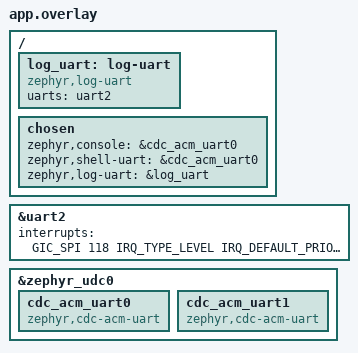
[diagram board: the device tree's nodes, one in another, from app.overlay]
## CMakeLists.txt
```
# SPDX-License-Identifier: Apache-2.0
cmake_minimum_required(VERSION 3.20.0)
find_package(Zephyr REQUIRED HINTS $ENV{ZEPHYR_BASE})
project(moru)

# 빌드 시각. configure 시점에 정해진다 — build.sh 가 -p always 라 매번 갱신되지만,
# ninja 만 직접 돌리면 옛 시각이 남는다.
# __DATE__/__TIME__ 대신 CMake 를 쓰는 이유는 재현 빌드다. ccache 영향은
# 어느 쪽이든 이 두 파일 재컴파일로 같다.
string(TIMESTAMP MORU_BUILD_TIME "%Y-%m-%d %H:%M:%S" UTC)
target_compile_definitions(app PRIVATE MORU_BUILD_TIME="${MORU_BUILD_TIME} UTC")

#
# ⚠ 작업 트리가 더러운지(커밋 전 변경이 있는지) 박는다.
#
# 왜 필요한가: APP_BUILD_VERSION 은 `git describe` 에 **--dirty 가 없다.**
# 그래서 **커밋 전 트리로 빌드한 이미지가 HEAD 해시로 찍힌다.** 2026-11-07 에
# 실기에서 "8 MiB 상한이 없는 커밋(54da428)" 으로 보이는 이미지가 실제로는
# 상한을 갖고 있어 한참 혼동했다.
#
# 왜 여기서 하는가: Zephyr 의 app_version.h 는 **별도 cmake 스크립트 호출**로
# 생성되고 최상위 -DAPP_BUILD_VERSION 이 그 호출에 전달되지 않는다
# (cmake/gen_version_h.cmake 는 자기 인자만 본다). 게다가 그 매크로는
# **따옴표 없는 토큰**이라 `-dirty` 같은 하이픈을 담기에도 부적합하다.
# 그래서 문자열로 직접 주입한다.
execute_process(COMMAND git -C ${CMAKE_CURRENT_SOURCE_DIR} status --porcelain
                OUTPUT_VARIABLE MORU_GIT_STATUS
                OUTPUT_STRIP_TRAILING_WHITESPACE ERROR_QUIET)
if(MORU_GIT_STATUS STREQUAL "")
  set(MORU_GIT_DIRTY "")
else()
  set(MORU_GIT_DIRTY "-dirty")
endif()
target_compile_definitions(app PRIVATE MORU_GIT_DIRTY="${MORU_GIT_DIRTY}")

# 보드 모델은 moru_boot.c 의 고정 문자열이다.
# DT 루트의 model 속성은 바인딩에 없어 매크로가 생성되지 않고(DT_PROP 불가)
# dt_prop() 도 비어 돌아온다. zephyr.dts 를 정규식으로 긁는 방법은 되지만,
# 이 앱은 이미 보드 전용이고(GPIO0 주소·SoC 문구가 하드코딩) 이 값은 배너
# 장식 한 줄이라 그 취약함을 안고 갈 값이 아니다.
# → 그래서 src/moru.h 의 MORU_MODEL 고정 문자열로 둔다.

# 소스 네 개를 모두 빌드한다 (2026-11-06, B1·B2 완료 상태).
#   main.c       LED 하트비트 + main
#   moru_mark.c  초기 부팅 동기 마커 — uart2 에 직접 (USB 가 무음일 때의 눈)
#   moru_boot.c  Linux dmesg 형식 부팅 메시지 + 로그 타임스탬프 기준점
#   moru_shell.c `moru` 명령 (info · reboot)
#
# ⚠ 과거에 moru_stage.c 가 있었고 2026-11-06 에 삭제했다 — PRE_KERNEL_1 에서
#   device_map() 을 불러 보드를 죽이는 파일이었다. kernel/init.c 의
#   z_mem_manage_init()(:293)이 PRE_KERNEL_1(:560)·PRE_KERNEL_2(:564) 보다
#   뒤, POST_KERNEL(:300) 바로 앞에서 돈다. 진단 장치가 피검체를 죽인
#   사례이고 (docs/bringup-rules.md 규칙 5), 남겨 두면 다음 사람이 빌드에
#   넣고 같은 함정을 밟으므로 지웠다.
# drivers/hwinfo/hwinfo_rk3566.h 를 "hwinfo_rk3566.h" 로 쓸 수 있게 한다.
# (저장소 루트는 CMakeLists.txt 의 두 단계 위)
target_include_directories(app PRIVATE
  ${CMAKE_CURRENT_SOURCE_DIR}/../../drivers/hwinfo
  # udc_dwc3_regs.h — moru usb 가 dwc3 레지스터를 직접 읽는다. 드라이버
  # 소스는 건드리지 않고 레지스터 정의만 재사용하므로 중복 정의가 없다.
  ${CMAKE_CURRENT_SOURCE_DIR}/../../drivers/usb/udc)

target_sources(app PRIVATE src/main.c src/moru_mark.c src/moru_boot.c
                           src/moru_shell.c src/moru_usbd.c
                           src/moru_htop.c src/moru_fatal.c)
```

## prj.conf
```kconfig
# USB 디바이스 스택은 켜되, 콘솔은 UART2 로 둔다.
#
# 스택이 켜져야 usbd 가 udc_init()/udc_enable() 을 부르고 그래야 dwc3
# 드라이버가 실제로 돈다. 콘솔을 CDC-ACM 으로 보내면 드라이버가 실패할 때
# 실패 원인을 알려 줄 로그 자체가 사라지므로, 콘솔은 UART2 에 남긴다.
CONFIG_SERIAL=y
CONFIG_CONSOLE=y
CONFIG_UART_CONSOLE=y
CONFIG_STDOUT_CONSOLE=y
CONFIG_UART_LINE_CTRL=y

CONFIG_USB_DEVICE_STACK_NEXT=y
CONFIG_USBD_CDC_ACM_CLASS=y
# 부팅 때 스택을 자동으로 올린다 — 앱 코드 없이 udc_init/udc_enable 이 불린다
# ⚠ 끈다 — 이 자동 경로는 CDC-ACM 인스턴스를 **하나만** 등록한다.
#   subsys/usb/device_next/app/cdc_acm_serial.c:65 가
#   usbd_register_class(..., "cdc_acm_0", ...) 를 부르고 함수 이름도
#   register_cdc_acm_0 다. 그 Kconfig help 도 "다른 USB 기능이 필요 없는
#   앱의 기본 시리얼 백엔드 전용" 이라고 적고 있다.
#
#   실기 증상(2026-11-06): cdc_acm_uart1 노드를 추가해도 호스트에 포트가
#   하나만 보였다. 드라이버 인스턴스는 생겨 device_is_ready() 가 true 인데
#   USB 디스크립터에는 인터페이스가 2개(CDC 하나)뿐이었다.
#
#   → src/moru_usbd.c 가 대신 구성한다. usbd_register_all_classes() 로
#     사용 가능한 인스턴스를 전부 등록하므로 CDC 를 더 늘려도 코드를
#     고치지 않는다.
CONFIG_CDC_ACM_SERIAL_INITIALIZE_AT_BOOT=n
# ⚠ CDC_ACM_SERIAL_PID·PRODUCT_STRING 은 INITIALIZE_AT_BOOT 하위 심볼이라
#   그것을 끈 지금은 존재하지 않는다. VID·PID·문자열은 src/moru_usbd.c 가
#   정한다 (MORU_USB_VID 0x2fe3 · MORU_USB_PID 0x0005 ·
#   "MoruLab" / "MoruLab Zephyr RTOS"). 호스트에 보이는 이름이므로 그쪽을
#   고친다.

# 진단이 목적이므로 USB 쪽 로그를 모두 켠다
CONFIG_LOG=y
# DBG 는 줄 수가 너무 많다 — 타이밍에 영향을 준다. 판정에 필요한 INF 만.
CONFIG_UDC_DRIVER_LOG_LEVEL_INF=y
CONFIG_USBD_LOG_LEVEL_INF=y
# ⚠ INF 로 두면 **수신한 모든 바이트가 hexdump 된다** —
#   usbd_cdc_acm.c:315 의 LOG_HEXDUMP_INF(buf->data, buf->len, "").
#   OTA 로 171 KB 를 받으면 로그가 폭발하고, 그것을 다시 CDC 로 내보내려
#   하면서 전송이 사실상 멈춘다(실기에서 120초를 넘겼다). cdc_acm_fifo_read
#   안의 LOG_INF 도 같다. Zephyr 공식 overlay-usb.conf 가
#   USBD_CDC_ACM_LOG_LEVEL_OFF=y 를 쓰는 이유가 이것이다.
#
#   WRN 으로 둔다 — OFF 가 아니라 WRN 인 이유는 "Invoked by inappropriate
#   context" 같은 실제 경고는 봐야 하기 때문이다.
# ⚠ WRN 이어야 한다 — INF 면 usbd_cdc_acm.c:315 의 LOG_HEXDUMP_INF 가
#   수신 바이트를 전부 찍어 대량 전송을 따라가지 못한다. 진단 때 INF 로
#   켜서 수신 경로가 정상임을 확인했고(64바이트 완전 수신, 4096 에서
#   96 %), 그 2 % 부족도 hexdump 지연 때문이었다.
#   "Invoked by inappropriate context" 같은 실제 경고는 WRN 에서 보인다.
CONFIG_USBD_CDC_ACM_LOG_LEVEL_WRN=y

# ⚠ 즉시 출력 모드. 어딘가에서 멈추면 버퍼에 남은 로그가 날아가므로,
#   한 줄씩 바로 내보내 '어디까지 갔는지' 를 알 수 있게 한다.
# ⚠ 즉시 모드를 쓰지 않는다 — 이것이 열거 실패의 원인이었다.
#
#   즉시 모드는 로그 한 줄을 그 자리에서 UART 로 밀어내며 스레드를 멈춘다.
#   115200 에서 100자는 약 9 ms 이고, 리셋 처리 하나가 12줄 이상을 찍으니
#   100 ms 가 넘는다. USB 규격은 SET_ADDRESS 가 50 ms 안에 완료되어야
#   한다고 정하므로, 로그가 그 예산을 통째로 먹고 호스트가 타임아웃·리셋을
#   반복했다 (실기에서 26~38회).
#
#   지연 모드는 로그 스레드가 따로 내보내므로 드라이버 스레드를 막지 않는다.
CONFIG_LOG_MODE_DEFERRED=y
# main 이 USB CDC-ACM 이라 **터미널을 열 때까지 백엔드가 붙지 않는다.**
# deferred 로그는 그동안 이 버퍼에 쌓이고, 넘치면 오래된 것부터 조용히
# 버려진다 — 그러면 부팅 로그 앞부분이 사라져 "무음"처럼 보인다.
# 부팅 로그가 ~45줄이라 8192 로도 될 것 같지만 여유가 없다. 8 KiB 를 더
# 쓰는 값이 1 MiB 중에서 싸다 (교란 변수를 미리 없앤다).
CONFIG_LOG_BUFFER_SIZE=16384

# ⚠ 실기에서 "xlat tables low: 7 of 8 in use" 경고가 났다. device_map 을
#   여러 번 쓰므로(dwc3, GPIO, USB2PHY GRF) 기본값 8 로는 빠듯하다.
CONFIG_MAX_XLAT_TABLES=24

# ⚠ 실기에서 크래시했다 — ELR 과 lr 이 같은 쓰레기 주소(0xffffff80ffffffd0)
#   였다. ret 이 망가진 복귀 주소로 돌아간 것, 즉 스택 손상이다.
#
#   드라이버 스레드 기본값이 1024 바이트인데 CONFIG_LOG_MODE_IMMEDIATE 는
#   호출자 스택에서 로그를 포매팅·출력하므로 훨씬 많이 쓴다. 핸들러 하나가
#   여러 줄을 찍으면 넘친다.
CONFIG_UDC_DWC3_STACK_SIZE=4096

# 다음에 또 넘치면 '쓰레기 점프' 가 아니라 명확한 메시지로 보이게 한다.
# 스택 손상이 원인이 아니었다면 이 설정들이 그것도 알려 준다.
# CONFIG_HW_STACK_PROTECTION 은 이 arm64 타깃에서 지원되지 않는다.
# 소프트웨어 감시자(sentinel)로 대신한다 — 넘치면 명확히 알려 준다.
# 넘침을 쓰레기 점프가 아니라 명확한 메시지로 보이게 한다.
# (기동을 깨뜨린 것은 FRAME_POINTER 였고 이것은 무해했다)
CONFIG_STACK_SENTINEL=y
CONFIG_THREAD_NAME=y
CONFIG_THREAD_STACK_INFO=y
# CONFIG_STACK_USAGE=y   # 기동 실패 원인 가리기 위해 임시로 끔
# CONFIG_INIT_STACKS=y   # 기동 실패 원인 가리기 위해 임시로 끔

# CONFIG_DEBUG_THREAD_INFO=y   # 기동 실패 원인 가리기 위해 임시로 끔

# ── 실험 1 (2026-11-06): 역추적 재시험 ────────────────────────────────
#
# 과거 기록: FRAME_POINTER / EXCEPTION_STACK_TRACE 를 켜면 Zephyr 가
# 기동조차 하지 못했다 (LED 도 콘솔도 무음).
#
# ⚠ 그 증상은 INIT_STACKS 와 **똑같았고, 그쪽 원인은 EL2 데이터 캐시였다.**
#   (ARM64_DCACHE_ALL_OPS + ARM64_BOOT_DISABLE_DCACHE 로 해결, 실기 확인)
#   프레임 포인터도 스택을 더 건드리므로 같은 원인일 수 있다. 캐시 두 설정이
#   켜진 지금 구성에서 다시 시험한다.
#
# 한 줄로 체인 넷이 켜진다 — 쪼갤 수 없다:
#   ARCH_HAS_STACKWALK      default y, depends on FRAME_POINTER
#                           (arch/arm64/core/Kconfig:210, CPU_CORTEX_A 안)
#     -> ARCH_STACKWALK     default y (arch/Kconfig:489)
#       -> EXCEPTION_STACK_TRACE  default y (subsys/debug/Kconfig:317)
# 즉 FRAME_POINTER 없이는 나머지가 선택 자체가 안 된다. 과거 기록이
# "둘 다"로 적은 것은 사실상 하나였다.
#
# 전제조건은 이미 넣었다 — SHELL_STACK_SIZE=4096 (실측 71 % 근거, 아래).
# 프레임 포인터는 스택을 더 쓰므로 3072 에서 시험하면 "기동 실패"와
# "셸 스택 넘침"을 가릴 수 없다.
#
# 판정:
#   부팅 + Moru > → 역추적을 되찾았다. 남은 B1~B4 의 디버깅 비용이 내려간다
#   무음           → 캐시와 무관한 별개 원인. 이 줄을 지우고 돌아간다
#                    (동작판 사본: 스크래치패드 zephyr-usbmain-good.bin
#                     146048 B, config-usbmain-good)
#
# ✅ 안전한 검증 수단이 함께 생겼다 — CONFIG_KERNEL_THREAD_SHELL_UNWIND 가
#   자동으로 켜져 `kernel thread unwind [<id16진수>]` 명령이 붙는다
#   (subsys/shell/modules/kernel_service/thread/unwind.c:53, 인자를 빼면
#    현재 스레드). 살아 있는 스레드의 콜 스택을 찍으므로 **고장 코드를
#   넣지 않고** 역추적을 확인할 수 있다 — 일부러 깨뜨리는 것은 규칙 5 가
#   금지하는 패턴이고(moru_stage.c 가 그렇게 태어났다) 이제 필요도 없다.
#
#   주소를 함수 이름으로 바꾸려면:
#     ~/zephyr-sdk-1.0.1/gnu/aarch64-zephyr-elf/bin/aarch64-zephyr-elf-addr2line \
#       -e /tmp/claude-501/rz3e-build/zephyr/zephyr.elf -f -C <주소>
CONFIG_FRAME_POINTER=y

# ⚠ usbd 스레드 스택 — Zephyr 기본값 1024 로는 넘친다 (실기 확인:
#   "FATAL ERROR 2: Stack overflow", Current thread: usbd).
#
#   1024 는 32비트 MCU 기준 값이다. arm64 는 64비트 레지스터 31개라
#   문맥 저장만으로도 크고, CONFIG_LOG_MODE_IMMEDIATE 는 로그를 호출자
#   스택에서 포매팅한다. 이 보드의 다른 스택(main·workqueue·ISR·idle)은
#   이미 4096 인데 이것만 기본값으로 남아 있었다.
CONFIG_USBD_THREAD_STACK_SIZE=4096

# 직렬번호 문자열 디스크립터를 위해 hwinfo 를 켠다.
# 구현은 drivers/hwinfo/hwinfo_rk3566.c (자리표 — 주석 참고).
CONFIG_HWINFO=y

# ── 1단계 최소 시험: usbuart 와의 차이는 이 두 줄이 전부다 ────────────────
#
# 5줄까지 줄였는데도 무음이었다. 그 중 셋(SHELL_STACK_SIZE, DW8250,
# LOG_BACKEND_UART)은 내가 추측으로 더한 것이고 기능에 필수가 아니다.
# 기능이 요구하는 최소치만 남긴다. 이것도 무음이면 CONFIG_SHELL 자체가
# 지금 이 보드와 맞지 않는다는 뜻이고, 그건 훨씬 근본적인 발견이다.
#
# 뺀 것과 이유:
#   SHELL_STACK_SIZE=8192  → 기본값(arm64 3072)을 쓴다. 더한 근거가 추측이었다
#   UART_NS16550_DW8250_DW_APB=y → poll_out 은 LSR_THRE 를 쓰므로 콘솔과
#       무관하고(uart_ns16550.c:986), RK3566 에 USR 이 있는지 TRM 으로
#       확인하지 않았다
#   LOG_BACKEND_UART=y → 셸 백엔드와 같은 UART 에 두 번째 백엔드를 붙이는
#       것이라 그 자체가 미검증이다
CONFIG_SHELL=y
CONFIG_SHELL_PROMPT_UART="Moru > "

# ⚠ 셸 백엔드를 폴링 모드로. SHELL=y 가 이 보드에 들여오는 유일하게 새로운
#   것이 UART 인터럽트이고, 이 보드는 그 경로를 한 번도 쓴 적이 없다
#   (기존 세 앱은 전부 셸이 없다). 폴링이면 인터럽트를 아예 쓰지 않는다.
#   이것으로 부팅하면 인터럽트 경로가 범인으로 확정되고, 그래도 죽으면
#   인터럽트 가설은 완전히 폐기된다.
# ⚠ 인터럽트 구동으로 바꿨다 (2026-11-06) — 로그가 잘리는 문제 때문이다.
#
#   증상: 터미널을 열면 부팅 로그가 쏟아지다 중간에 끊긴다
#   (ep 0x81 mps=16 까지만). 그런데 shell stats show 는 Lost logs: 0 이다.
#
#   원인: cdc_acm_poll_out(usbd_cdc_acm.c:1014)이 링버퍼가 차면
#   **조용히 버린다** (flow_ctrl 이 false — DT hw-flow-control 이 없다).
#   터미널을 열기 전 로그가 그렇게 버려진다. Lost logs 는 셸 로그 백엔드의
#   큐 드롭만 세므로 이 버림은 집계되지 않는다.
#
#   해결: CONFIG_SHELL_BACKEND_SERIAL_CHECK_DTR — DTR 이 올 때까지 TX 를
#   막아 버리지 않고 기다린다. 그것이 **인터럽트 모드 전용**이다
#   (Kconfig.backends:148).
#
#   폴링을 쓴 원래 이유는 uart2 의 GIC 트리거 타입이 불확실했기
#   때문인데, **셸이 CDC 로 옮겨간 뒤 그 이유가 사라졌다** — CDC 의
#   인터럽트는 USB 컨트롤러(SPI 169, 라이브 DT 로 검증)가 낸다.
#   진단 빌드(셸이 UART2)는 diag-uart.conf 로 폴링을 되돌린다.
CONFIG_SHELL_BACKEND_SERIAL_API_INTERRUPT_DRIVEN=y
# ⚠ CHECK_DTR 을 **껐다** (2026-11-06 저녁). 같은 기전이 반대로 물었다.
#
#   증상: 터미널 앱에서 수 초마다 "Connection lost — auto-reconnecting" 이
#   반복되고 타이핑한 글자가 유실됐다 (`moru htop` 이 `mhtop` 으로 들어갔다).
#
#   가린 방법: 포트를 쥐고 **DTR 을 내리지 않는** 리더로 140초간 1초마다
#   `kernel uptime` 을 물었다 — 끊김 0, 응답 90/90, 재열거 0, 재부팅 0,
#   가동시간 단조 증가. 보드·케이블·전원은 멀쩡하다. 침묵이 아니라
#   **90회 전부 응답했다는 양성 증거**다.
#
#   원인: uart_dtr_check()(shell_uart.c:135-153)가 DTR 이 내려가 있으면
#   셸 TX 를 막는다. 앱이 DTR 을 흔들거나 tty 를 여닫으면 출력이 멈추고,
#   앱은 그 침묵을 끊김으로 보고 다시 열며, 그 창의 입력은 버려진다.
#
#   왜 이제 꺼도 되는가: 이 설정을 켠 이유(위 — 터미널을 열기 전 CDC
#   poll_out 이 로그를 조용히 버리는 것)가 **약해졌다.** app.overlay 의
#   chosen zephyr,log-uart 로 로그를 uart2 에 복제했으므로 터미널을 열기
#   전 로그도 전부 uart2 에 남는다. CDC 에서 버려지는 것이 더 이상 유일한
#   기록이 아니다.
#
#   대가: 터미널을 열기 전 CDC 출력은 버려진다(열고 엔터 한 번이면
#   프롬프트가 나온다). 이득: 터미널 앱의 DTR 동작에 의존하지 않는다.
# CONFIG_SHELL_BACKEND_SERIAL_CHECK_DTR=y

# ⚠ 셸 로그 백엔드의 큐 — CHECK_DTR 만으로는 부족했다.
#
#   CHECK_DTR 을 켜니 로그가 EP 6개까지 온전히 나왔지만
#   "--- 27 messages dropped ---" 가 남았다. CHECK_DTR 이 **버림을
#   집계되게** 만든 것이고(이전에는 CDC poll_out 이 조용히 버렸다),
#   이제 드롭되는 곳은 셸 로그 백엔드의 큐다.
#
#   기본값은 큐 512 바이트 · 타임아웃 100 ms 다. 부팅 로그가 60여 줄이고
#   터미널을 열기까지 수십 초가 걸리므로 모자란다.
#   타임아웃을 늘리면 로그를 넣는 쪽이 더 기다려 준다 — 부팅 중 몇백 ms
#   지연은 무해하고(deferred 모드라 호출자를 막지 않는다) 로그를 잃는
#   것보다 낫다.
CONFIG_SHELL_BACKEND_SERIAL_LOG_MESSAGE_QUEUE_SIZE=8192
CONFIG_SHELL_BACKEND_SERIAL_LOG_MESSAGE_QUEUE_TIMEOUT=1000

# ── KERNEL_SHELL 이 imply 로 끌고 오는 것들을 명시적으로 끈다 ────────────
#
# .config 를 usbuart 와 직접 비교해 보니 내가 쓴 2줄이 아니라 70여 개가
# 달랐다. CONFIG_SHELL=y 한 줄이 KERNEL_SHELL·DEVICE_SHELL·DEVMEM_SHELL·
# DATE_SHELL 을 기본 y 로 켜고, KERNEL_SHELL 이 다시 INIT_STACKS 와
# THREAD_MONITOR 를 imply 한다. imply 는 강제가 아니라 끌 수 있다.
#
# INIT_STACKS 가 특히 중요하다 — 동작하는 usbuart 에는 없고 실패한 모든
# 빌드에 있었다. usbuart/prj.conf:61-62 가 "기동 실패 원인 가리려고 껐다"
# 고 적어 둔 그 설정이다. arm64 리셋 경로(reset.S:204-215)에서 MMU 와
# 콘솔보다 먼저 ISR 스택을 0xAA 로 칠한다. 이 보드의 수치로는 그 루프가
# 정상 종료하는 것을 확인했지만(시작·끝 차이 0xFF8), 상관관계가 분명하니
# 변수를 줄인다.
#
# DEVMEM_SHELL 은 임의 물리 메모리 쓰기라 어차피 끄려던 것이다.
# ── A 시험: 범인 특정 ────────────────────────────────────────────────────
#
# 네 설정을 전부 끄니 부팅했다. 이제 어느 것이 범인인지 가린다.
#
# 기능을 직접 시험하는 쪽으로 설계했다. kernel thread list/stacks 는
# INIT_STACKS + THREAD_MONITOR + THREAD_STACK_INFO 셋 모두를 요구한다
# (thread/Kconfig:16-18,26-28). 그래서 그 셋을 켜고 나머지 둘은 끈다.
#   부팅하면 → 사용자가 고른 "스레드·스택" 명령을 바로 얻는다
#   실패하면 → 범인이 INIT_STACKS 또는 THREAD_MONITOR 로 좁혀진다
#              (DEVMEM/DATE 는 셸 명령만 더하므로 무죄 쪽에 가깝다)
#
# THREAD_STACK_INFO 와 THREAD_NAME 은 usbuart 설정에 이미 있다.
# A-2 시험 결과 반영:
#   넷 다 끈 판(777091b)  → 부팅 ✅ (Moru > 프롬프트·help 동작)
#   INIT_STACKS+THREAD_MONITOR 켠 판(464a4ce) → 무음 ❌
#   → DEVMEM_SHELL·DATE_SHELL 은 무죄 (두 판 모두 꺼져 있었다)
#   → 범인은 INIT_STACKS 또는 THREAD_MONITOR
#
# 이제 둘을 가른다. INIT_STACKS 는 arm64 리셋 경로(reset.S:204-215)에서
# MMU·콘솔보다 먼저 ISR 스택을 0xAA 로 칠하고, THREAD_MONITOR 는
# 스레드 생성 시 기록부만 잇는다. 전자가 훨씬 유력하므로 그것만 끈다.
#   부팅하면 → INIT_STACKS 가 범인. thread list/stacks 를 포기한다
#              (THREAD_MONITOR 는 남으므로 thread suspend/resume/kill 은 쓴다)
#   무음이면 → THREAD_MONITOR 가 범인. 예상 밖이고 더 파야 한다
#
# ── 실험 B0 (2026-11-06): EL2 데이터 캐시 가설을 가른다 ──────────────────
#
# 결과(fc0d8eb): INIT_STACKS 가 유죄로 입증됐다. 그러나 기전은 설명되지
# 않았다 — reset.S:199-215 의 칠하기 루프는 이 보드 수치로 정상 종료한다.
#
# 2026-11-06 에 유력한 가설이 섰다. 범인은 루프가 아니라 **그 루프가 도는
# 시점의 캐시 상태**다. 근거 셋 다 확인했다:
#
#   ① Zephyr 가 EL2 에서 부팅한다 — U-Boot 가 EL2(SPSR 0x3c9)에서 go 한다
#      (실측, docs/hardware-verified.md:1348)
#   ② arch/arm64/core/reset.c:158 의 dcache clean+disable 블록이
#      컴파일조차 되지 않는다 — CONFIG_ARM64_DCACHE_ALL_OPS 가 n 이라
#      거기 의존하는 ARM64_BOOT_DISABLE_DCACHE 는 선택 자체가 안 된다
#   ③ arch/arm64/core/Kconfig:446 의 help 가 정확히 이 위험을 기술한다 —
#      "To make it safe, if data cache is enabled in case of Zephyr is
#       booting from EL2, enable this option, it will clean and invalidate
#       all data cache and then disable data cache"
#
# 기전(가설): go 는 booti 와 달리 캐시를 정리하지 않으므로 EL2 의 MMU·
# dcache 가 켜진 채 진입한다 → 0xAA 칠하기가 ISR 스택 4 KiB 를 dcache 에
# dirty 로 남긴다 → switch_el 로 EL1 에 내려가면 SCTLR_EL1 이 초기값이라
# MMU·C 가 꺼져 이후 스택 접근은 캐시를 우회해 DRAM 으로 간다 → 나중에
# 그 stale dirty 줄이 evict 되며 EL1 이 DRAM 에 써 둔 값을 0xAA 로 덮는다
# → 복귀 주소 손상 → PRE_KERNEL_1 전에 무음.
#
# INIT_STACKS=n 이면 EL2 구간에서 더럽혀지는 것이 함수 프레임 수백 바이트
# 뿐이고 그 영역은 EL1 이 곧 다시 쓴다. 4 KiB 를 칠할 때만 "EL1 이 아직
# 쓰지 않은 깊은 영역"에 stale 줄이 남는다 — "루프는 정상인데 켜면 죽는"
# 모순이 이것으로 설명된다.
#
# ✅ 결과 (2026-11-06 실기): 부팅했다. 가설 확정.
#   Moru > 프롬프트 · USB CDC-ACM 열거 · <err> 0줄 ·
#   kernel thread list 와 kernel thread stacks 둘 다 동작한다. 후자는
#   IRQ 00 = ISR 스택까지 보여준다 (usage 500/4096) — 0xAA 칠하기가
#   정상 작동한다는 직접 증거다.
#
#   INIT_STACKS 는 양쪽 다 y 인데 캐시 두 설정 유무로 결과가 뒤집혔다:
#     464a4ce (캐시 설정 없음) → 무음 ❌
#     ef6780f (캐시 설정 있음) → 부팅 ✅
#   즉 진짜 원인은 INIT_STACKS 가 아니라 EL2 부팅 시 dcache 미정리였다.
#
# ⚠ 아래 캐시 두 줄을 지우면 보드가 부팅하지 않는다. 이 보드의 필수
#   설정이다. 동작 확인된 바이너리 사본은 세션 스크래치패드의
#   zephyr-known-good.bin (146056 B, 캐시 설정 없이 INIT_STACKS=n 판).
#
CONFIG_INIT_STACKS=y
CONFIG_ARM64_DCACHE_ALL_OPS=y
CONFIG_ARM64_BOOT_DISABLE_DCACHE=y

CONFIG_THREAD_MONITOR=y
CONFIG_DEVMEM_SHELL=n
CONFIG_DATE_SHELL=n

# 셸 스레드 스택. arm64 기본 3072 는 이 구성에 부족하다 — 실측 근거:
#   kernel thread stacks 출력에서 shell_uart 가 2196/3072 (71 %) 였다.
#   다른 스레드는 모두 4096 인데 이것만 3072 였고 여유가 876 바이트다.
#   arm64 는 레지스터 31개 문맥만으로도 크니 명령이 몇 단계 깊어지면
#   넘친다. 되찾은 thread stacks 명령으로 추측 없이 결정했다.
# ⚠ FRAME_POINTER 재시험의 전제조건이기도 하다 — 프레임 포인터를 켜면
#   스택 사용이 늘어 71 % 에서 넘칠 수 있고, 그러면 "기동 실패"와 "셸
#   스택 넘침"을 가릴 수 없다. 교란 변수를 먼저 없앤다.
CONFIG_SHELL_STACK_SIZE=4096


# ── main 은 USB · 안 되면 UART 1개 (2026-11-06 사용자 확정 원칙) ────────
#
# chosen 지정은 app.overlay 가 한다 (console·shell → cdc_acm_uart0).
# 진단은 diag-uart.overlay 로 빌드해 uart2 로 되돌린다. 이 파일에는
# 모드별 Kconfig 차이가 없다 — 셸 백엔드가 폴링 모드라 양쪽 같은 코드다.
#
# 셸 백엔드를 폴링으로 두는 근거 (CDC 에서도 안전하다):
#   usbd_cdc_acm.c:1014 의 poll_out 은 링버퍼가 차면 ISR 안이거나
#   flow_ctrl 이 false 일 때 **버린다**. flow_ctrl 은 DT 의
#   hw-flow-control 에서 오고(:1380) 우리 CDC 노드엔 없으므로 false 다.
#   즉 터미널을 열지 않아도 블록하지 않는다. 따라서
#   CONFIG_SHELL_BACKEND_SERIAL_CHECK_DTR(인터럽트 모드 전용,
#   Kconfig.backends:148) 가 필요 없고, 검증된 폴링 모드를 유지한다.
#
# ── USB 가 무음일 때 가르는 순서 (이 묶음의 실패 분석 계획) ────────────
#   ① UART2 에 [2][<S][S>][<U][U>][M] 마커가 나오는가
#        → 나오면 커널은 살았고 CDC 경로 문제다. ②로
#        → 안 나오면 부팅 자체가 깨졌다. 캐시 두 설정과 진입점을 먼저 본다
#   ② 마커 중 [S>] 까지 나오는가 → 셸 백엔드 init 통과 여부
#   ③ ioreg 에 장치가 보이는가 → 열거 여부 (셸과 무관하게 판정된다)
#   ④ ①②③ 다 되는데 프롬프트가 없으면 → 터미널에서 엔터를 쳐 본다
#        (열기 전 출력은 버려진다 — 위 poll_out 설명)
#   ⑤ 그래도 안 되면 → diag-uart.overlay 빌드로 카드를 교체한다


# ── B1: Linux dmesg 형식 부팅 메시지 (2026-11-06) ──────────────────────
#
# Zephyr 기본 배너(*** Booting Zephyr OS build ... ***)를 끄고 우리 배너로
# 대체한다. src/moru_boot.c 가 SYS_INIT 우선순위로 순서를 보장한다.
#
# ⚠ 이 한 줄이 CONFIG_EARLY_CONSOLE 도 함께 끈다 — BOOT_BANNER 가 그것을
#   select 하기 때문이다 (lib/os/Kconfig:150). 무해하다: EARLY_CONSOLE 은
#   stdout 드라이버를 평소보다 일찍 초기화하는 디버깅 옵션이고
#   (subsys/debug/Kconfig:164) 우리는 stdout 을 쓰지 않는다. 초기 출력은
#   src/moru_mark.c 가 uart_poll_out 으로 직접 하고, 로그는 deferred 다.
#   BOOT_BANNER 가 select 하던 PRINTK 는 셸이 따로 요구해 y 로 남는다(확인).
CONFIG_BOOT_BANNER=n

# "[    0.123456] " 형식 — Linux 와 같다 (log_output.c:213-220).
# ⚠ 해상도는 1 ms 다. 이 보드는 24 MHz 라 log_core.c:282 의
#   sys_clock_hw_cycles_per_sec() > 1000000 검사를 통과하지 못하고
#   default_lf_get_timestamp(k_uptime_get(), 1000 Hz)를 쓴다. 즉 마지막 세
#   자리는 항상 0 이다. 랩어라운드는 없다(64비트 uptime).
CONFIG_LOG_OUTPUT_FORMAT_LINUX_TIMESTAMP=y

# ⚠ 필수 — 없으면 약 179 초에 시각이 0 으로 되돌아간다.
#
#   log_msg.h:33-36 이 이 설정 없으면 log_timestamp_t 를 uint32_t 로 둔다.
#   moru_boot.c 가 타임스탬프를 24 MHz 사이클 카운터로 바꿨으므로
#   2^32 / 24e6 = 178.96 s 에서 감긴다. 그러면 [  178.9xx] 다음 줄이
#   [    0.0xx] 로 찍히고 moru info 의 "가동"(k_uptime_get)과 어긋난다.
#
#   ⚠ 계획서(보정 3)의 "랩어라운드 없음" 은 **기본 타임스탬프
#     (k_uptime_get, 1 kHz)** 기준이었다. moru_boot.c 가 24 MHz 로 바꾸면서
#     그 전제를 깼다. 설정 하나를 바꾸면 다른 분석의 전제가 무효가 되는
#     사례다 (docs/bringup-rules.md 규칙 3 — .config 로 확인한다).
#   대가는 로그 메시지당 4바이트다. 16384 버퍼에서 무시할 수 있다.
CONFIG_LOG_TIMESTAMP_64BIT=y

# 셸 로그 백엔드의 접두사를 걷어낸다 (shell_log_backend.c:160-166).
#   "<inf> " 제거 · "[main] " 제거
# ⚠ 소스 태그(moru:·udc_dwc3:)는 **남긴다** — Linux dmesg 도
#   "[    0.1] usb 1-1: ..." 처럼 서브시스템 접두를 갖는다. 출처가 구분되어
#   읽기도 쉽다. 그래서 SHELL_LOG_OUTPUT_SKIP_SOURCE 는 기본 n 그대로 둔다.
# ── 로그를 uart2 에도 복제 (2026-11-06) ────────────────────────────────
# USB 가 죽으면 콘솔·셸이 함께 죽어 관측 수단이 시험 대상에 매달린다.
# chosen zephyr,log-uart = &log_uart (app.overlay) 가 대상을 uart2 로 잡는다.
# 기본값은 'y if !SHELL_BACKEND_SERIAL' 이라 우리 구성에서는 n 이 되므로
# 명시해야 한다. 셸 백엔드와 공존한다 (depends 는 UART_CONSOLE 뿐).
CONFIG_LOG_BACKEND_UART=y

CONFIG_SHELL_LOG_OUTPUT_LEVEL=n
CONFIG_SHELL_LOG_OUTPUT_THREAD=n

# ── B1 종료 조건 ───────────────────────────────────────────────────────
#   ① [    0.123456] 형식으로 배너·단계 메시지가 나온다
#   ② shell stats show 의 Lost logs: 0  — 부팅 메시지가 ~15줄 늘었다.
#      기준선은 11-06 USB main 에서 측정한 0 이다 (UART 빌드 값이 아니다)
#   ③ 호스트에 "MoruLab Zephyr RTOS" · PID 0x0005 로 보인다 (ioreg)
#   ④ 열거 유지 · <err> 0줄 · kernel thread unwind 여전히 동작


# ── B2: 커널 상태·진단 셸 모듈 (2026-11-06) ────────────────────────────
#
# ⚠ kernel heap 은 HEAP_MEM_POOL_SIZE > 0 이 없으면 **컴파일조차 되지
#   않는다** — heap.c:8 이 파일 전체를 #if K_HEAP_MEM_POOL_SIZE > 0 으로
#   감싼다. SYS_HEAP_RUNTIME_STATS 만으로는 명령이 생기지 않는다.
CONFIG_HEAP_MEM_POOL_SIZE=8192
CONFIG_SYS_HEAP_RUNTIME_STATS=y
# moru htop 의 CPU% 에 필요하다. 이 한 줄이 SCHED_THREAD_USAGE ·
# SCHED_THREAD_USAGE_ALL · SCHED_THREAD_USAGE_AUTO_ENABLE 을 기본 y 로
# 끌고 온다(kernel/Kconfig:410-463). USE_SWITCH=y 라서
# INSTRUMENT_THREAD_SWITCHING 훅은 붙지 않는다 — 전환 경로에서 바로 센다.
# 덤으로 내장 `kernel thread list` 가 스레드별 실행 사이클과 부팅 이후
# 비율을 찍는다(kernel_service/thread/list.c:30-48). 그래서 moru 에는
# ps·mem 을 만들지 않는다.
# ⚠ RK3566 의 UART 는 Synopsys DW_apb_uart 다 — 이 설정이 **필수**다.
#
#   이것이 꺼져 있으면 ns16550 의 ISR 이 콜백 없는 포트에서 **아무것도 하지
#   않는다**(uart_ns16550.c:1405-1416). 켜면 IIR 을 읽고 IID==0x7
#   (DesignWare busy detect)이면 USR 을 읽어 그 인터럽트를 지운다.
#
#   왜 치명적이었나 (2026-11-06 밤에 밤새 쫓은 것):
#     ① ns16550 이 init 에서 uart2 의 GIC 라인을 무조건 켠다(:1947).
#     ② uart2 를 인터럽트 모드로 쓰는 것이 없다 — 셸은 CDC, 로그 백엔드는
#        uart_poll_out 폴링. 그래서 콜백이 없고 조건을 지울 사람이 없다.
#     ③ app.overlay 가 트리거를 LEVEL 로 고쳐 두었다(하드웨어 기준으로는
#        맞다 — Linux rk356x-base.dtsi 도 LEVEL_HIGH 다). 레벨이면 조건이
#        서 있는 동안 GIC 가 끝없이 재발화한다.
#     ④ DW busy detect 는 **IER 로 막을 수 없다.** 실측: moru uart2 가
#        IER 0x00 인데 IIR 0xc7(IID 0x7)을 보여 줬고, 한 번 읽으니
#        0xc1 로 바뀌어 래치였음이 확인됐다.
#   결과: IRQ 150(= GIC_SPI 118 + 32, uart2)이 반복 발화한다. 정상 빌드는
#   견디지만 THREAD_RUNTIME_STATS 를 켜면 전환↔ISR 무한 루프가 되어
#   POST_KERNEL 에 도달하지 못한다(실측: 전환 48,936회 / stop 97,871회).
CONFIG_UART_NS16550_DW8250_DW_APB=y

# moru htop 의 창 단위 CPU% 에 필요하다. 이 한 줄이 SCHED_THREAD_USAGE ·
# _ALL · AUTO_ENABLE 을 기본 y 로 끌고 온다(kernel/Kconfig:410-463).
# ⚠ 위 DW8250 설정 없이 이것만 켜면 **부팅하지 않는다** — 위 설명 참고.
CONFIG_THREAD_RUNTIME_STATS=y

# hwinfo devid / reset_cause. 링크 걱정 없다 —
# drivers/hwinfo/CMakeLists.txt:8 이 CONFIG_HWINFO 면 hwinfo_weak_impl.c 를
# 항상 링크하므로, 우리가 구현하지 않은 reset_cause 는 -ENOSYS 를 돌려준다.
CONFIG_HWINFO_SHELL=y

# log status / enable / disable / list_backends
CONFIG_LOG_CMDS=y
CONFIG_LOG_RUNTIME_FILTERING=y

# ── B2 종료 조건 ───────────────────────────────────────────────────────
#   ① moru info 의 값이 전부 맞다 (버전·해시·보드·CPU·메모리·칩ID·콘솔)
#   ② 타임스탬프가 0 부터 시작한다 — 첫 로그가 [    0.000xxx]
#      (B1 에서는 6.699 초였다. CNTVCT_EL0 가 SoC 리셋부터 돌기 때문)
#   ②-b **부팅 후 3분(180 s)을 넘겨도 시각이 단조 증가한다** —
#      LOG_TIMESTAMP_64BIT 가 없으면 178.96 s 에서 0 으로 감긴다.
#      moru info 의 "가동" 값과 로그 시각을 비교해 확인한다
#   ③ 배너에 "Bootloader: 6.3xx s before Zephyr entry" 가 나온다
#   ④ kernel heap · hwinfo devid · log status · app version 동작
#   ⑤ 열거 유지 · <err> 0줄 · Lost logs: 0


# ── B4(앞당김): moru reboot — Kconfig 추가 0개 ─────────────────────────
#
# CONFIG_REBOOT 과 CONFIG_PM_CPU_OPS 를 **켜지 않는다.** 후자는 psci_init 이
# PRE_KERNEL_1 에서 PSCI_VERSION SMC 를 쏘는데 그건 콘솔보다 먼저다 — BL31 이
# 응답하지 않으면 무음으로 죽어 FRAME_POINTER 때와 증상이 똑같아져 원인
# 구분이 불가능해진다 (계획 보정 2).
#
# 대신 moru_shell.c 가 arm_smccc_smc() 를 셸 핸들러에서 직접 부른다.
# arch/Kconfig:50 에서 ARM64 가 HAS_ARM_SMCCC 를 무조건 select 하므로
# 추가 Kconfig 가 0개다. 위험한 SMC 는 사람이 명령을 칠 때만 나가고,
# 그 시점엔 콘솔이 살아 있고 안내 메시지도 이미 나간 뒤다.
#
# ── moru reboot 종료 조건 ──────────────────────────────────────────────
#   ① moru reboot probe 가 PSCI 버전을 찍는다 (BL31 이 응답한다)
#      얼면 그 자체가 결론이다 — 콘솔에 "probe: issuing..." 이 남는다
#   ② moru reboot 이 실제로 재부팅한다. **판정은 UART2 마커로 한다** —
#      USB 가 끊겨 셸도 끊기므로 USB 로는 확인할 수 없다. 마커
#      [2][<S][S>][<U][U>][M] 이 다시 나오면 재부팅된 것이다
#   ③ 재부팅 뒤 USB 가 다시 열거된다 (호스트가 포트를 다시 잡는다)


# ── OTA 1단계: 두 번째 CDC-ACM (데이터 포트) ───────────────────────────
#
# 노드는 app.overlay 가 만든다 (cdc_acm_uart1). 여기서는 늘어난 버퍼
# 요구만 맞춘다.
#
# ⚠ 이 둘을 올리는 것은 "교란 변수 제거" 다. 두 번째 인스턴스가 bulk
#   IN/OUT·notification 버퍼를 더 쓰는데, 부족하면 "열거는 되는데 데이터가
#   안 온다" 같은 모호한 증상이 나와 원인을 가릴 수 없다. 기본값
#   (POOL 1024 · COUNT 16)으로도 될 것으로 보이지만(두 CDC 의 상주 버퍼
#   추정 ~350 B), 1 KiB 를 더 쓰는 값이 1 MiB 중에서 싸다.
# OTA 페이로드 무결성 검사 — crc32_ieee() 가 이 설정 없이는 링크되지 않는다
# (undefined reference to crc32_ieee, 실제로 빌드가 실패했다)
CONFIG_CRC=y

CONFIG_UDC_BUF_POOL_SIZE=2048
CONFIG_UDC_BUF_COUNT=24

# ── OTA 1단계 종료 조건 ────────────────────────────────────────────────
#   ① 호스트에 CDC 포트가 **둘** 생긴다 (ls /dev/cu.usbmodem*)
#   ② 첫 번째 포트에서 셸이 그대로 동작한다 (Moru > · moru info)
#   ③ 로그에 bNumInterfaces 가 2 -> 4 로 늘어난다
#   ④ <err> 0줄 · 열거 유지 · Lost logs: 0
#   ⑤ moru info 가 데이터 포트 이름을 찍는다


# ── OTA 1단계-A 종료 조건 (앱이 직접 usbd 구성) ────────────────────────
#   ① 호스트에 CDC 포트가 **둘** 생긴다 (ls /dev/cu.usbmodem*)
#   ② ioreg 의 인터페이스가 **4개** 다 (CDC 하나당 control+data 2개).
#      1단계에서는 2개였고 그것이 "CDC 하나만 등록됐다" 는 증거였다
#   ③ 첫 번째 포트에서 셸이 동작한다 · 호스트 이름 "MoruLab Zephyr RTOS"
#   ④ 직렬번호가 OTP 칩 ID 그대로다 (hwinfo 디스크립터가 살아 있는가)
#   ⑤ <err> 0줄 · Lost logs: 0 · kernel thread unwind 동작
#
# ⚠ 이 묶음은 USB 초기화를 전면 교체하므로 **깨지면 USB 셸을 잃는다.**
#   그래서 먼저 진단 빌드(diag-uart.overlay, 셸이 UART2)로 굽는다 —
#   USB 가 전혀 안 올라와도 셸이 살아 있어 로그를 읽을 수 있다.
#     ./build.sh "$PWD/apps/moru" /tmp/claude-501/rz3e-diag \
#                "$PWD/apps/moru/diag-uart.overlay"
#   그 빌드에서 ①②가 확인되면 USB main 빌드로 올린다.

# LED 상태 표시는 soc_init/moru_led.c. fatal 핸들러는 moru_fatal.c 가 갖고
# 그 끝에서 moru_led_fatal() 을 부르므로 모듈 쪽 핸들러는 끈다.
CONFIG_MORU_LED_FATAL_HANDLER=n
```

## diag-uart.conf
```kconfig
# 진단 빌드 전용 — 셸이 UART2 일 때만 쓴다.
#
#   ./build.sh "$PWD/apps/moru" /tmp/claude-501/rz3e-diag \
#              "$PWD/apps/moru/diag-uart.overlay"  (+ 이 conf)
#
# ⚠ 셸 백엔드를 폴링으로 되돌린다.
#
#   main 빌드(셸이 CDC)는 인터럽트 모드를 쓴다 — CHECK_DTR 이 그 모드에서만
#   되고, 그게 없으면 터미널을 열기 전 로그가 CDC poll_out 에서 조용히
#   버려진다(usbd_cdc_acm.c:1014).
#
#   그러나 UART2 에서 인터럽트 모드를 쓰려면 GIC 트리거 타입이 맞아야
#   한다. 인트리 rk3568.dtsi 는 IRQ_TYPE_EDGE 로 선언하는데 Linux DT 는
#   LEVEL 이고, **TRM 으로 확정하지 못했다**
#   (docs/trm-grounding.md §5 의 2번). 그래서 진단 빌드는 검증된 폴링을
#   유지한다 — 진단 수단이 진단 대상이 되면 안 된다.
CONFIG_SHELL_BACKEND_SERIAL_API_POLLING=y
```

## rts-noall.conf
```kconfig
# THREAD_RUNTIME_STATS 를 켜되 SCHED_THREAD_USAGE_ALL 만 끈 판.
#
# 의심 지점을 정확히 제거한다 — kernel/init.c:398-402 의
#   _kernel.cpus[id].usage = &_kernel.usage[id];
# 가 ALL 아래에 있다. 즉 struct _cpu 와 _kernel 의 배치를 바꾸는 부분이다.
# htop 은 k_thread_runtime_stats_all_get() 을 쓰지 않으므로 이 구성에서도
# 창 단위 CPU% 가 동작한다 — 뜨면 기능까지 얻는다.
CONFIG_THREAD_RUNTIME_STATS=y
CONFIG_SCHED_THREAD_USAGE_ALL=n
```

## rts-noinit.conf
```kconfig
# THREAD_RUNTIME_STATS 를 켜고 INIT_STACKS 만 끈 판.
#
# 왜 이 변수인가: INIT_STACKS 는 이 보드가 이미 데인 설정이다 —
# reset.S:199-215 가 EL2 에서 ISR 스택을 0xAA 로 칠하고, 그 더티 캐시 라인이
# 나중에 DRAM 을 덮어 부팅이 조용히 죽었다(ARM64_BOOT_DISABLE_DCACHE 로
# 막아 둔 상태다). THREAD_RUNTIME_STATS 는 그 IRQ 스택 위에서 C 함수를
# 부르게 만든다(isr_wrapper.S:53 의 bl z_sched_usage_stop).
#
# QEMU 로는 이 혈통을 시험할 수 없다 — ARM64_BOOT_DISABLE_DCACHE 는
# z_arm64_el2_init() 안에서만 동작하고(reset.c:158) QEMU 는 EL1 로 들어간다.
#
# 뜨면: 스택 칠하기와의 상호작용이다. 그러면 kernel thread stacks 와
#       htop 의 CPU% 중 하나를 고르는 문제로 바뀐다.
# 안 뜨면: INIT_STACKS 는 무죄이고 다른 곳이다.
CONFIG_THREAD_RUNTIME_STATS=y
CONFIG_INIT_STACKS=n
```

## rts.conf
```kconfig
# THREAD_RUNTIME_STATS 를 그냥 켠 판. 기본 하위 설정(SCHED_THREAD_USAGE ·
# _ALL · AUTO_ENABLE)이 전부 따라온다 — 즉 우리가 실제로 원하는 구성이다.
#
# 이 판의 목적은 이등분이 아니라 **죽는 자리를 말하게 하는 것**이다.
# moru_fatal.c 의 핸들러가 uart2 에 ESR·FAR·ELR 을 동기로 찍고, 그 계기는
# moru_fault 로 양성 대조를 거쳤다 (FAR 이 일부러 읽은 주소와 일치,
# addr2line 이 ELR 을 그 소스 줄로 풀어냈다).
#
# 기대하는 결과는 둘 중 하나다.
#   ① === MORU FATAL === 이 찍힌다 → ELR 을 addr2line 에 넣으면 끝난다
#   ② 또 아무 말 없이 멈춘다 → fault 가 아니라 '멈춤'(락·무한대기)이거나
#     예외 벡터가 서기 전에 죽는 것이다. 그 자체가 큰 정보다
CONFIG_THREAD_RUNTIME_STATS=y
```

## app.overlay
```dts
/*
 * CDC-ACM 노드를 만들고 **콘솔·셸을 그것으로 돌린다.**
 *
 * SPDX-License-Identifier: Apache-2.0
 *
 * ── 원칙 (2026-11-06 사용자 확정) ────────────────────────────────────
 *   main 은 USB 다. 안 되면 UART 1개만 써서 들여다본다.
 *
 * 그래서 이 오버레이가 chosen 을 CDC 로 지정하고, 진단용으로
 * diag-uart.overlay (chosen 을 uart2 로 되돌림) 를 따로 둔다.
 *
 * ⚠ 열거 전 로그는 터미널을 열 때까지 보이지 않는다. LOG_MODE_DEFERRED 라
 *   버퍼에 쌓이고 백엔드가 붙은 뒤 쏟아진다 (그래서 prj.conf 가
 *   LOG_BUFFER_SIZE 를 16384 로 올려 둔다). 부팅이 열거 전에 죽으면
 *   아무것도 안 보이므로, src/moru_mark.c 의 동기 마커는 chosen 과
 *   무관하게 **uart2 에 직접** 찍는다 — 그것이 유일한 초기 관측 수단이다.
 *
 * ⚠ CDC 의 poll_out 은 링버퍼가 차면 **버린다** (블록하지 않는다 —
 *   usbd_cdc_acm.c:1014, flow_ctrl 이 DT hw-flow-control 에서 오고 우리
 *   노드엔 없으므로 false). 그래서 셸 백엔드를 폴링 모드로 유지할 수 있고
 *   CONFIG_SHELL_BACKEND_SERIAL_CHECK_DTR(인터럽트 모드 전용) 가 필요 없다.
 *   대가는 터미널을 열기 전 출력이 버려지는 것 — 열고 엔터를 치면 된다.
 */

#include <zephyr/dt-bindings/interrupt-controller/arm-gic.h>

/*
 * ⚠ uart2 인터럽트를 레벨 트리거로 바로잡는다.
 *
 * 인트리 rk3568.dtsi:81 이 IRQ_TYPE_EDGE 로 선언했으나 RK356x 의 UART 는
 * 레벨 트리거다 (Linux rk356x-base.dtsi 는 IRQ_TYPE_LEVEL_HIGH 를 쓴다).
 * intc_gicv3.c:208 의 `if (flags & IRQ_TYPE_EDGE)` 가 이 값을 실제로 GIC
 * ICFGR 에 쓰므로, 틀린 채로 두면 SPI 118 이 edge 로 설정된다.
 *
 * 이 보드에서 UART 인터럽트를 켜는 것은 이 앱이 처음이다 — 기존 세 앱은
 * CONFIG_SHELL 이 없어 이 경로를 쓴 적이 없다.
 *
 * 인트리 dtsi 대신 앱 오버레이에서 고친다. 보드 DTS 는 지금 유일하게
 * 부팅하는 파일이라 건드리지 않는다.
 */
&uart2 {
	interrupts = <GIC_SPI 118 IRQ_TYPE_LEVEL IRQ_DEFAULT_PRIORITY>;
};

&zephyr_udc0 {
	/* 셸·로그 (chosen zephyr,console / zephyr,shell-uart) */
	cdc_acm_uart0: cdc_acm_uart0 {
		compatible = "zephyr,cdc-acm-uart";
	};

	/*
	 * OTA 데이터 포트 (2026-11-06).
	 *
	 * 왜 두 번째가 필요한가: 셸이 cdc_acm_uart0 를 독점하므로 펌웨어
	 * 바이너리를 받을 통로가 없다. 같은 포트로 받으려면 셸을 멈추고 raw
	 * 모드로 바꿔야 하는데, 그러면 전송 중 상태를 물어볼 수단이 사라진다.
	 * 인스턴스를 하나 더 두면 호스트에 포트가 둘 생겨
	 *   /dev/cu.usbmodem…  (셸)      ← 사람이 쓴다
	 *   /dev/cu.usbmodem…  (데이터)  ← cat zephyr.bin > 로 쏟아붓는다
	 * 가 되고, 전송 중에도 셸로 진행 상황을 볼 수 있다.
	 *
	 * 비용: USB 인터페이스 2개·엔드포인트 3개(notification IN + bulk IN +
	 * bulk OUT)가 늘어난다. 두 CDC 가 EP1~EP4 만 쓰므로 DT 의
	 * num-bidir-endpoints = <8> 로 충분하다 (HW 는 16).
	 */
	cdc_acm_uart1: cdc_acm_uart1 {
		compatible = "zephyr,cdc-acm-uart";
	};
};

/ {
	/*
	 * 로그를 uart2 에도 복제한다 (2026-11-06, UART 어댑터 연결 뒤).
	 *
	 * 왜 필요한가: 셸·콘솔이 USB 에 있으므로 **USB 가 죽으면 로그도 함께
	 * 사라진다.** 그래서 USB 전원 관리(suspend/resume)를 시험할 수가 없었다 —
	 * 관측 수단이 시험 대상에 매달려 있었다. 이 보드는 급전까지 같은 USB-C
	 * 포트에서 받으므로(VCC 미연결) 포트를 유휴로 두면 전원까지 흔들린다.
	 *
	 * uart2 백엔드는 그 사슬을 끊는다. USB 가 죽든 보드가 재부팅하든
	 * uart2 에는 계속 찍힌다. src/moru_mark.c 의 동기 마커가 초기 부팅만
	 * 보여 주던 것을 전 구간으로 넓히는 셈이다.
	 *
	 * ⚠ 백엔드는 uart_poll_out 을 쓴다(동기 폴링) — 인터럽트를 쓰지 않으므로
	 *   uart2 의 GIC 트리거 타입(아직 미검증)이 걸리지 않는다.
	 * ⚠ 115200 은 줄당 약 9 ms 다. LOG_MODE_DEFERRED 라 로그 처리 스레드가
	 *   그 시간을 쓰고, CDC 작업큐와는 별개 스레드다. 다만 로그가 폭주하면
	 *   메시지가 버려질 수 있다 — 그래서 레벨은 올리지 않는다.
	 */
	log_uart: log-uart {
		compatible = "zephyr,log-uart";
		uarts = <&uart2>;
	};

	chosen {
		zephyr,console = &cdc_acm_uart0;
		zephyr,shell-uart = &cdc_acm_uart0;
		zephyr,log-uart = &log_uart;
	};
};
```

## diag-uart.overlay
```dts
/*
 * 진단 모드 — 콘솔·셸을 UART2 로 되돌린다.
 *
 * SPDX-License-Identifier: Apache-2.0
 *
 * 평상시 main 은 USB CDC-ACM 이다 (app.overlay). USB 가 안 되면 이 오버레이로
 * 빌드해 UART 1개로 들여다본다 — 2026-11-06 사용자 확정 원칙.
 *
 *   ./build.sh "$(pwd)/apps/moru" /tmp/claude-501/rz3e-diag \
 *              "$(pwd)/apps/moru/diag-uart.overlay"
 *
 * chosen 은 나중에 적용된 오버레이가 이기므로 app.overlay 의 CDC 지정을
 * 이 파일이 덮는다. Kconfig 변경은 없다 — 셸 백엔드가 폴링 모드라
 * (CONFIG_SHELL_BACKEND_SERIAL_API_POLLING) 양쪽에서 같은 코드가 돈다.
 */

/ {
	chosen {
		zephyr,console = &uart2;
		zephyr,shell-uart = &uart2;
	};
};
```

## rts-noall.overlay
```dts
/* 변수 분리 실험용 — DT 변경 없음 */
/ { };
```

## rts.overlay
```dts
/* 실험용 — DT 변경 없음 */
/ { };
```

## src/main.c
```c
/*
 * MoruLab Zephyr RTOS — Radxa ZERO 3E.
 *
 * SPDX-License-Identifier: Apache-2.0
 *
 * 셸·로그는 UART2. 부팅 메시지는 moru_boot.c. 여기서는 생존 신호 LED 만 돌린다.
 * printk 는 쓰지 않는다 (동기 출력이 USB 열거를 깨뜨렸다).
 */

#include <zephyr/kernel.h>
#include <zephyr/sys/sys_io.h>
#include <zephyr/sys/device_mmio.h>
#include <zephyr/logging/log.h>

LOG_MODULE_REGISTER(main, LOG_LEVEL_INF);

#include "moru.h"

#define GPIO0_PHYS		0xfdd60000UL
#define GPIO0_SIZE		0x100
#define RK_GPIO_SWPORT_DR_L	0x00
#define RK_GPIO_SWPORT_DDR_L	0x08
#define LED_PIN			0U

static inline uint32_t rk_gpio_val(uint32_t pin, bool on)
{
	uint32_t we = BIT(pin + 16);

	return on ? (we | BIT(pin)) : we;
}

static void led_thread(void *a, void *b, void *c)
{
	mm_reg_t base;

	ARG_UNUSED(a); ARG_UNUSED(b); ARG_UNUSED(c);

	device_map(&base, GPIO0_PHYS, GPIO0_SIZE, K_MEM_CACHE_NONE);
	sys_write32(rk_gpio_val(LED_PIN, true), base + RK_GPIO_SWPORT_DDR_L);

	while (1) {
		sys_write32(rk_gpio_val(LED_PIN, true),
			    base + RK_GPIO_SWPORT_DR_L);
		k_msleep(2000);
		sys_write32(rk_gpio_val(LED_PIN, false),
			    base + RK_GPIO_SWPORT_DR_L);
		k_msleep(2000);
	}
}

/* ⚠ 스택 4096 — arm64 에서 1024 는 크래시한다 (usbuart 앱 주석 참고) */
K_THREAD_DEFINE(led_tid, 4096, led_thread, NULL, NULL, NULL, 7, 0, 0);

int main(void)
{
	moru_mark("[M]");
	LOG_INF("MoruLab Zephyr RTOS is up — 'help' 로 명령 목록");
	k_sleep(K_FOREVER);
	return 0;
}
```

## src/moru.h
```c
/*
 * apps/moru 내부 공용 선언.
 *
 * SPDX-License-Identifier: Apache-2.0
 */

#ifndef MORU_H_
#define MORU_H_

#include <stdint.h>

/** 초기 부팅 동기 마커 — uart2 에 직접 찍는다 (moru_mark.c). */
void moru_mark(const char *s);

/** ARM implementer·part 번호를 사람이 읽는 이름으로 (moru_boot.c). */
const char *moru_cpu_part_name(uint32_t implementer, uint32_t part);

/**
 * 모델 이름.
 *
 * DT 루트의 model 속성은 바인딩에 없어 매크로가 생성되지 않으므로
 * (DT_PROP 불가, dt_prop() 도 빈 값) 고정 문자열로 둔다. 이 앱은 이미 보드
 * 전용이다 — SoC 문구와 main.c 의 GPIO0 주소도 하드코딩이다.
 */
#define MORU_MODEL "Radxa ZERO 3E"

/**
 * 전원 투입부터 Zephyr 의 PRE_KERNEL_1 까지 걸린 시간 (µs).
 *
 * 로그 타임스탬프는 PRE_KERNEL_1 을 0 으로 맞추므로(moru_boot.c 의
 * moru_cycle_timestamp), 그 앞 구간은 이 값으로만 남는다.
 *
 * ⚠ U-Boot·TF-A BL31 뿐 아니라 **Zephyr 자신의 arm64 초기 부팅**
 *   (reset.S 의 MMU·캐시 설정, EL2→EL1 전환, bss 지우기)도 포함된다.
 *   그 구간을 따로 측정한 적은 없다.
 *
 * 0 이면 측정하지 못한 것이다 (CNTFRQ_EL0 가 터무니없는 값이었던 경우).
 */
uint64_t moru_preboot_us(void);

/**
 * `moru htop` 핸들러 (moru_htop.c). 명령 등록은 moru_shell.c 가 한다.
 *
 * ⚠ 이 핸들러는 **돌아오지 않고 루프를 돈다** (q · Ctrl-C · 600초 상한).
 *   그동안 shell_process() 가 멈추므로 다른 셸 명령도, 셸 로그 백엔드
 *   비우기도 함께 멈춘다. 로그는 uart2 백엔드로 계속 나간다.
 */
struct shell;
int cmd_moru_htop(const struct shell *sh, size_t argc, char **argv);

#endif /* MORU_H_ */
```

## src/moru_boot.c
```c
/*
 * MoruLab Zephyr RTOS — 부팅 메시지 (Linux dmesg 형식)
 *
 * SPDX-License-Identifier: Apache-2.0
 *
 * 모든 출력은 LOG_INF 다. printk 는 동기 블로킹이라 쓰지 않는다.
 * 값은 DT·Kconfig·시스템 레지스터에서 읽은 것만 찍는다.
 */

#include <zephyr/kernel.h>
#include <zephyr/init.h>
#include <zephyr/devicetree.h>
#include <zephyr/app_version.h>
#include <zephyr/version.h>
#include <zephyr/sys/util.h>
#include <zephyr/arch/arm64/lib_helpers.h>
#include <zephyr/arch/arm64/cpu.h>
#include <zephyr/logging/log.h>
#include <zephyr/logging/log_ctrl.h>

#include "moru.h"

LOG_MODULE_REGISTER(moru, LOG_LEVEL_INF);

#ifndef MORU_BUILD_TIME
#define MORU_BUILD_TIME "unknown"
#endif

#define SEP "===================================================="

/*
 * 로그 타임스탬프를 24 MHz 사이클 카운터로 바꾼다.
 *
 * Zephyr 기본값은 log_core.c:282 가 사이클 주파수를 보고 고르는데, 이 보드는
 * 24 MHz > 1 MHz 라 k_uptime_get()(1000 Hz)이 선택된다. 그러면 Linux 형식
 * 출력의 µs 끝 세 자리가 늘 0 이 되어 "[    0.123000]" 처럼 찍힌다.
 * arm arch timer 가 TIMER_HAS_64BIT_CYCLE_COUNTER 를 select 하므로
 * k_cycle_get_64() 를 쓸 수 있고, 그걸 걸면 진짜 µs 가 나온다.
 *
 * PRE_KERNEL_1 우선순위 0 에 둔다 — 다른 어떤 로그보다 먼저 바꿔야 한다.
 * 시간 기준이 중간에 바뀌면 log_output 이 모든 줄을 '현재' 주파수로 나누므로
 * 앞선 줄들의 시각이 틀리게 찍힌다. k_cycle_get_64() 는 CNTVCT_EL0 를 읽을
 * 뿐이고 그 카운터는 리셋부터 돌므로 이 시점에도 안전하다.
 */
static uint64_t moru_cycle_base;   /* Zephyr 진입 시점의 CNTVCT_EL0 */
static uint64_t moru_preboot;      /* 그 값을 µs 로 바꾼 것 */

uint64_t moru_preboot_us(void)
{
	return moru_preboot;
}

/*
 * ⚠ 진입 시점을 0 으로 맞춘다 (2026-11-06).
 *
 * CNTVCT_EL0 는 SoC 리셋부터 돌기 때문에 그대로 쓰면 첫 로그가
 * "[    6.699229]" 로 찍힌다 — U-Boot 가 쓴 ~6.3 초가 포함된 값이다.
 * Linux dmesg 는 커널 시작을 0 으로 하므로 기준을 맞춘다. 부트로더가
 * 쓴 시간은 버리지 않고 moru_preboot_us() 로 남겨 배너에 한 줄 찍는다.
 */
static log_timestamp_t moru_cycle_timestamp(void)
{
	return (log_timestamp_t)(k_cycle_get_64() - moru_cycle_base);
}

static int moru_boot_timestamp(void)
{
	uint64_t freq = read_cntfrq_el0();

	/*
	 * CNTFRQ_EL0 를 펌웨어가 채우지 않는 경우가 있다. 값이 터무니없으면
	 * 기본 타임스탬프(1 ms)를 그대로 쓴다 — 해상도를 잃는 편이 시각이
	 * 엉뚱하게 찍히는 것보다 낫다.
	 */
	if (freq < 1000000U || freq > 1000000000U) {
		return 0;
	}

	moru_cycle_base = k_cycle_get_64();
	moru_preboot = (moru_cycle_base * 1000000ULL) / freq;

	(void)log_set_timestamp_func(moru_cycle_timestamp, (uint32_t)freq);
	return 0;
}
SYS_INIT(moru_boot_timestamp, PRE_KERNEL_1, 0);

/* lib_helpers.h 에는 midr_el1·ctr_el0 접근자가 없어 read_sysreg() 를 쓴다 */
#define read_midr_el1()	read_sysreg(midr_el1)
#define read_ctr_el0()	read_sysreg(ctr_el0)

const char *moru_cpu_part_name(uint32_t implementer, uint32_t part)
{
	if (implementer != 0x41) {
		return "unknown";
	}
	switch (part) {
	case 0xd03: return "Cortex-A53";
	case 0xd04: return "Cortex-A35";
	case 0xd05: return "Cortex-A55";
	case 0xd07: return "Cortex-A57";
	case 0xd08: return "Cortex-A72";
	case 0xd09: return "Cortex-A73";
	case 0xd0a: return "Cortex-A75";
	case 0xd0b: return "Cortex-A76";
	default:    return "unknown";
	}
}

static int moru_boot_banner(void)
{
	uint64_t midr = read_midr_el1();
	uint32_t part = (midr >> 4) & 0xfff;
	uint32_t impl = (midr >> 24) & 0xff;

	LOG_INF(SEP);
	LOG_INF("MoruLab Zephyr RTOS %s (build %s)", APP_VERSION_STRING,
		STRINGIFY(APP_BUILD_VERSION));
	/*
	 * 커밋 해시를 함께 찍는다 — 4.4.99 는 릴리스가 아니라 main 개발
	 * 표시이고 같은 문자열이 수천 커밋을 가리킨다. 부팅 로그는 그대로
	 * 붙여 전달되는 것이므로 여기에 식별자가 있어야 한다.
	 */
	LOG_INF("Zephyr %s (%s), built %s", KERNEL_VERSION_STRING,
		STRINGIFY(BUILD_VERSION), MORU_BUILD_TIME);
	/*
	 * 타임스탬프는 여기서부터 0 이므로 부트로더 구간은 이 줄로만 남는다.
	 * U-Boot(TF-A BL31 포함)가 전원 투입부터 go 까지 쓴 시간이다.
	 */
	if (moru_preboot_us() != 0U) {
		/*
		 * ⚠ 구간은 "전원 투입(CNTVCT_EL0 = 0) → Zephyr 의 PRE_KERNEL_1"
		 *   이다. U-Boot·TF-A BL31 뿐 아니라 Zephyr 자신의 arm64 초기
		 *   부팅(reset.S 의 MMU·캐시 설정, EL 전환, bss 지우기)도 포함
		 *   된다. 그 구간은 따로 측정한 적이 없다. 그래서 "Bootloader"
		 *   가 아니라 "Pre-kernel" 로 적는다.
		 */
		LOG_INF("Pre-kernel: %llu.%03llu s (power-on → PRE_KERNEL_1)",
			moru_preboot_us() / 1000000ULL,
			(moru_preboot_us() % 1000000ULL) / 1000ULL);
	}
	LOG_INF(SEP);
	LOG_INF("Machine model: %s", MORU_MODEL);
	LOG_INF("SoC: Rockchip RK3566 (%s SoC 정의 재사용)", CONFIG_SOC);
	LOG_INF("CPU: %s, MIDR 0x%08llx, EL%u, MPIDR 0x%08llx",
		moru_cpu_part_name(impl, part), (unsigned long long)midr,
		(unsigned int)GET_EL(read_currentel()),
		(unsigned long long)read_mpidr_el1());
	{
		uint64_t ctr = read_ctr_el0();
		/* DminLine = CTR_EL0[19:16], 단위는 4 B 워드 수의 log2 */
		uint32_t dline = 4U << ((ctr >> 16) & 0xf);

		LOG_INF("Cache: min D-line %u B (CTR_EL0 0x%08llx)", dline,
			(unsigned long long)ctr);
	}
	return 0;
}
SYS_INIT(moru_boot_banner, PRE_KERNEL_2, 1);

static int moru_boot_memory(void)
{
	uint64_t freq = read_cntfrq_el0();

	LOG_INF("Memory: 0x%08lx + %lu KiB (zephyr,sram)",
		(unsigned long)CONFIG_SRAM_BASE_ADDRESS,
		(unsigned long)CONFIG_SRAM_SIZE);
	LOG_INF("Timer: ARM arch timer %u.%06u MHz, %u ticks/s, %s",
		(unsigned int)(freq / 1000000U),
		(unsigned int)(freq % 1000000U),
		(unsigned int)CONFIG_SYS_CLOCK_TICKS_PER_SEC,
		IS_ENABLED(CONFIG_TICKLESS_KERNEL) ? "tickless" : "periodic");
	return 0;
}
SYS_INIT(moru_boot_memory, PRE_KERNEL_2, 2);

static int moru_boot_console(void)
{
	/*
	 * ⚠ DT_PROP(CON, current_speed) 를 쓰면 안 된다 — main 이 USB CDC-ACM
	 *   이 되면서 chosen zephyr,console 이 cdc_acm_uart0 를 가리키는데
	 *   그 노드에는 current-speed 속성이 없어 **컴파일 오류**가 난다.
	 *   노드 이름만 찍고, 보율은 uart2 에서 직접 가져온다.
	 */
	LOG_INF("Console: %s (shell on same port)",
		DT_NODE_FULL_NAME(DT_CHOSEN(zephyr_console)));
	LOG_INF("Marker UART: %s %u 8N1 (early boot only)",
		DT_NODE_FULL_NAME(DT_NODELABEL(uart2)),
		(unsigned int)DT_PROP(DT_NODELABEL(uart2), current_speed));
	LOG_INF("Board: %s", CONFIG_BOARD_TARGET);
	return 0;
}
SYS_INIT(moru_boot_console, POST_KERNEL, 1);
```

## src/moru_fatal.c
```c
/*
 * 치명 오류를 uart2 에 **동기로** 찍는다.
 *
 * SPDX-License-Identifier: Apache-2.0
 *
 * 왜 필요한가
 * -----------
 * Zephyr 의 기본 fatal 경로는 LOG_ERR 로 찍는다. 이 앱은
 * `CONFIG_LOG_MODE_DEFERRED` + 셸 로그 백엔드(USB CDC)라서, **백엔드가 붙기
 * 전에 죽으면 그 메시지가 버퍼에 남고 아무것도 안 보인다.** 실제로
 * `CONFIG_THREAD_RUNTIME_STATS` 를 켠 판이 PRE_KERNEL_2 직후에 조용히
 * 죽었고, 마커 `[2]` 외에는 단 한 글자도 얻지 못했다 — 죽었는지 멈췄는지도
 * 구분할 수 없었다.
 *
 * 이 핸들러는 moru_mark 와 같은 길로 간다: uart2 에 `uart_poll_out` 으로
 * 직접, 동기로 밀어낸다. 로그·콘솔·USB·스케줄러가 전부 죽어도 나온다.
 *
 * ⚠ 이 안에서는 printf 계열과 LOG 를 쓰지 않는다. 16진수는 손으로 만든다 —
 *   fault 문맥에서 서식 엔진을 돌리는 것은 진단을 피검체로 만드는 일이다
 *   (규칙 5: 진단 코드는 피검체보다 단순해야 한다).
 *
 * ⚠ ESR/FAR 은 esf 에 없다. 시스템 레지스터에서 직접 읽는다. EL1 에서
 *   돌므로 ESR_EL1·FAR_EL1·ELR_EL1 이 유효하다.
 *
 * 읽는 법 (ESR_EL1):
 *   EC = ESR[31:26]  0x24/0x25 데이터 어보트 · 0x20/0x21 명령 어보트
 *                    0x22 PC 정렬 · 0x26 SP 정렬 · 0x2f SError
 *   FAR = 접근하려던 주소 (어보트일 때)
 *   ELR = 죽은 명령의 주소 → addr2line 으로 소스를 찾는다
 */

#include <zephyr/kernel.h>
#include <zephyr/fatal.h>
#include <zephyr/device.h>
#include <zephyr/drivers/uart.h>
#include <zephyr/arch/arm64/lib_helpers.h>

#include "moru.h"

static void f_puts(const struct device *d, const char *s)
{
	while (*s != '\0') {
		if (*s == '\n') {
			uart_poll_out(d, '\r');
		}
		uart_poll_out(d, *s++);
	}
}

/* 64비트를 고정 16자리 16진수로. 서식 엔진을 쓰지 않는다. */
static void f_hex64(const struct device *d, uint64_t v)
{
	static const char hx[] = "0123456789abcdef";

	f_puts(d, "0x");
	for (int i = 60; i >= 0; i -= 4) {
		uart_poll_out(d, hx[(v >> i) & 0xfU]);
	}
}

static void f_line(const struct device *d, const char *name, uint64_t v)
{
	f_puts(d, "  ");
	f_puts(d, name);
	f_puts(d, " = ");
	f_hex64(d, v);
	f_puts(d, "\n");
}

void k_sys_fatal_error_handler(unsigned int reason, const struct arch_esf *esf)
{
	/* ⚠ chosen 이 아니라 uart2 고정 — moru_mark.c 머리말과 같은 이유다 */
	const struct device *d = DEVICE_DT_GET(DT_NODELABEL(uart2));
	uint64_t esr = read_sysreg(esr_el1);
	uint64_t ec = (esr >> 26) & 0x3fULL;

	if (!device_is_ready(d)) {
		/* uart2 조차 아직이면 할 수 있는 것이 없다 */
		k_fatal_halt(reason);
	}

	f_puts(d, "\n=== MORU FATAL ===\n");
	f_line(d, "reason  ", (uint64_t)reason);
	f_line(d, "ESR_EL1 ", esr);
	f_line(d, "  EC    ", ec);
	f_line(d, "FAR_EL1 ", read_sysreg(far_el1));
	f_line(d, "ELR_EL1 ", read_sysreg(elr_el1));
	f_line(d, "CurrentEL", read_currentel());

	if (esf != NULL) {
		f_line(d, "esf.elr ", esf->elr);
		f_line(d, "esf.spsr", esf->spsr);
		f_line(d, "esf.lr  ", esf->lr);
		f_line(d, "esf.x0  ", esf->x0);
		f_line(d, "esf.x1  ", esf->x1);
	} else {
		f_puts(d, "  esf = NULL (어보트가 아니라 커널이 부른 것)\n");
	}

	/*
	 * EC 해독을 한 줄 붙인다 — 숫자만 보면 매번 TRM·ARM ARM 을 뒤진다.
	 * 출처: ARM ARM D17.2.37 ESR_EL1.
	 */
	f_puts(d, "  EC 뜻: ");
	switch (ec) {
	case 0x20: f_puts(d, "명령 어보트 (낮은 EL)\n"); break;
	case 0x21: f_puts(d, "명령 어보트 (같은 EL)\n"); break;
	case 0x22: f_puts(d, "PC 정렬 오류\n"); break;
	case 0x24: f_puts(d, "데이터 어보트 (낮은 EL)\n"); break;
	case 0x25: f_puts(d, "데이터 어보트 (같은 EL) — FAR 을 본다\n"); break;
	case 0x26: f_puts(d, "SP 정렬 오류\n"); break;
	case 0x2f: f_puts(d, "SError\n"); break;
	case 0x00: f_puts(d, "알 수 없음 (어보트가 아닐 수 있다)\n"); break;
	default:   f_puts(d, "위 EC 값을 ARM ARM 에서 찾는다\n"); break;
	}
	f_puts(d, "=== 멈춘다 ===\n");

	k_fatal_halt(reason);
}

/*
 * ⚠ 일부러 데이터 어보트를 낸다 — **진단기를 검증하기 위한 것**이다.
 *
 *   이 핸들러를 믿고 "조용히 죽었다 = fault 가 아니다" 라고 판정하려면,
 *   핸들러가 실제로 말을 하는지 먼저 증명해야 한다. 그러지 않으면 다음에
 *   또 침묵했을 때 "핸들러 고장" 과 "fault 아님" 을 구분할 수 없다 —
 *   오늘 uart2 점퍼로 똑같은 함정에 빠졌다(규칙 6, 체크리스트 9번).
 *
 *   되돌리기: 전원을 다시 넣으면 된다. 카드의 펌웨어는 그대로다.
 */
#include <zephyr/shell/shell.h>

static int cmd_moru_fault(const struct shell *sh, size_t argc, char **argv)
{
	ARG_UNUSED(argc);
	ARG_UNUSED(argv);

	shell_warn(sh, "일부러 데이터 어보트를 낸다 — uart2 를 보라.");
	shell_warn(sh, "보드는 멈춘다. 전원을 다시 넣으면 살아난다.");
	/* 셸 출력이 실제로 나갈 시간을 준다 */
	k_msleep(300);

	/*
	 * 매핑되지 않은 주소를 읽는다. volatile 로 최적화 제거를 막는다.
	 * 0x00000000 은 이 보드에서 매핑돼 있지 않다 (SRAM 은 0x40000000).
	 */
	{
		volatile uint64_t *bad = (volatile uint64_t *)0x10ULL;

		(void)*bad;
	}

	shell_error(sh, "어보트가 나지 않았다 — 이 주소가 매핑돼 있다");
	return -EIO;
}

SHELL_CMD_REGISTER(moru_fault, NULL,
		   "⚠ 일부러 fault 를 내 moru_fatal 진단기를 검증한다",
		   cmd_moru_fault);
```

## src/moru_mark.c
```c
/*
 * 동기 마커 — 어디까지 가다 멈추는지 콘솔로 직접 찍는다.
 *
 * 왜 이 방식인가.
 *  - printk 는 CONFIG_LOG_PRINTK 경로로 지연 로깅에 실려 갈 수 있어
 *    멈춤 직전의 출력이 버퍼에 남고 안 나온다.
 *  - LOG_INF 도 같은 이유로 못 쓴다 (백엔드가 뜨기 전엔 버퍼에만 쌓인다).
 *  - device_map 은 쓰지 않는다 — PRE_KERNEL_1 에서 그걸 불렀다가 보드를
 *    죽였다 (z_mem_manage_init 이 그보다 뒤에 돈다, kernel/init.c:293).
 *
 * uart_poll_out 은 LSR_THRE 를 폴링하고 스핀락만 쓴다
 * (uart_ns16550.c:979-996). uart2 는 PRE_KERNEL_1 우선순위 50 에서
 * 초기화되므로 PRE_KERNEL_2 이후라면 안전하다. 이 보드에서 지금까지
 * 모든 콘솔 출력이 이 경로로 나갔다.
 *
 * ── ⚠ chosen 이 아니라 uart2 에 직접 찍는다 (2026-11-06) ──────────────
 * main 이 USB CDC-ACM 으로 바뀌었다 (app.overlay). chosen zephyr,console
 * 을 따르면 이 마커가 CDC 로 가는데, USB 열거 전에는 한 글자도 나가지
 * 않아 **초기 관측 수단이 사라진다** — 그게 바로 이 파일의 존재 이유다.
 *
 * 그래서 노드를 uart2 로 고정한다. 보율은 걱정하지 않아도 된다:
 * ns16550 드라이버가 DT 의 current-speed(115200)를 스스로 적용한다
 * (uart_ns16550.c:2079 .uart_config.baudrate = DT_INST_PROP_OR(
 *  current_speed) → init → pm_action(TURN_ON) → configure →
 *  set_baud_rate, :654). 즉 **콘솔로 쓰이지 않아도 115200 으로 나온다.**
 *
 * 따라서 USB 가 무음일 때도 UART 어댑터만 꽂으면 어디까지 갔는지 보인다.
 * 진단 빌드(diag-uart.overlay)로 카드를 바꾸기 전에 먼저 이것을 본다.
 *
 * SPDX-License-Identifier: Apache-2.0
 */

#include <zephyr/kernel.h>
#include <zephyr/init.h>
#include <zephyr/device.h>
#include <zephyr/drivers/uart.h>

#include "moru.h"

void moru_mark(const char *s)
{
	/* chosen 이 아니라 uart2 고정 — 위 머리말 참고 */
	const struct device *con = DEVICE_DT_GET(DT_NODELABEL(uart2));

	if (!device_is_ready(con)) {
		return;
	}
	while (*s != '\0') {
		uart_poll_out(con, (unsigned char)*s++);
	}
}

static int m_pk2(void)      { moru_mark("[2]");  return 0; }
static int m_pre_shell(void){ moru_mark("[<S]"); return 0; }
static int m_post_shell(void){ moru_mark("[S>]"); return 0; }
static int m_pre_usb(void)  { moru_mark("[<U]"); return 0; }
static int m_post_usb(void) { moru_mark("[U>]"); return 0; }

SYS_INIT(m_pk2,        PRE_KERNEL_2, 99);
SYS_INIT(m_pre_shell,  POST_KERNEL,  89);	/* enable_shell_uart 는 90 */
SYS_INIT(m_post_shell, POST_KERNEL,  91);
SYS_INIT(m_pre_usb,    APPLICATION,  89);	/* cdc_acm_serial_init_device 는 90 */
SYS_INIT(m_post_usb,   APPLICATION,  91);
```

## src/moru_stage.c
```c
/*
 * 단계 표시 LED — 시리얼 없이 "어디까지 가다 멈췄는지" 를 읽는 장치.
 *
 * 왜 필요한가. main.c 의 LED 스레드는 우선순위 7 이라 main 스레드(0)가
 * 양보해야 비로소 돌아간다. 그래서 init 중에 어디서든 멈추면 LED 가 한 번도
 * 켜지지 않고, 셸이 못 뜨면 로그도 안 나와 보드가 완전히 무음이 된다.
 * 이 파일은 각 init 레벨에서 LED 를 그 단계 번호만큼 깜박인다. 사람이 세어
 * 본 마지막 횟수가 마지막으로 통과한 단계다.
 *
 *   1회 → PRE_KERNEL_1 통과
 *   2회 → PRE_KERNEL_2 통과
 *   3회 → POST_KERNEL 통과   (셸 백엔드가 여기서 뜬다)
 *   4회 → APPLICATION 통과   (USB 스택이 여기서 뜬다)
 *   그 뒤 2초 주기 느린 깜박임 → main() 도달, 정상
 *
 * 각 묶음 사이에 1.2초를 쉬어 횟수를 셀 수 있게 한다.
 *
 * 지연은 k_busy_wait() 가 아니라 nop 스핀 루프다 — 시스템 타이머는
 * PRE_KERNEL_2 우선순위 0 에서야 올라오므로 PRE_KERNEL_1 에서는 쓸 수 없다.
 * 그래서 시간이 정확하지 않다. 횟수만 세면 된다.
 *
 * SPDX-License-Identifier: Apache-2.0
 */

#include <zephyr/kernel.h>
#include <zephyr/init.h>
#include <zephyr/sys/sys_io.h>
#include <zephyr/sys/util.h>
#include <zephyr/kernel/mm.h>
#include <zephyr/device.h>

#define GPIO0_PHYS		0xfdd60000UL
#define GPIO0_SIZE		0x100
#define RK_GPIO_SWPORT_DR_L	0x00
#define RK_GPIO_SWPORT_DDR_L	0x08
#define LED_PIN			0U

/* 상위 16비트가 비트별 쓰기 허용(hiword mask)이다 */
static inline uint32_t rk_gpio_val(uint32_t pin, bool on)
{
	uint32_t we = BIT(pin + 16);

	return on ? (we | BIT(pin)) : we;
}

static mm_reg_t stage_gpio;
static bool stage_ready;

/* nop 스핀. 1 단위 ≈ 수십 µs 수준(정확하지 않다). */
static void stage_spin(uint32_t units)
{
	for (volatile uint32_t u = 0; u < units; u++) {
		for (volatile uint32_t i = 0; i < 2000U; i++) {
			__asm__ volatile("nop");
		}
	}
}

static void stage_led(bool on)
{
	if (!stage_ready) {
		return;
	}
	sys_write32(rk_gpio_val(LED_PIN, on), stage_gpio + RK_GPIO_SWPORT_DR_L);
}

static void stage_mark(uint32_t count)
{
	for (uint32_t n = 0; n < count; n++) {
		stage_led(true);
		stage_spin(60);
		stage_led(false);
		stage_spin(60);
	}
	stage_spin(600);	/* 묶음 사이 쉼 — 횟수를 셀 수 있게 */
}

/* ── 단계 1: 가장 먼저. GPIO 를 매핑하고 1회 깜박인다 ──────────────────── */
static int stage_pre_kernel_1(void)
{
	device_map(&stage_gpio, GPIO0_PHYS, GPIO0_SIZE, K_MEM_CACHE_NONE);
	sys_write32(rk_gpio_val(LED_PIN, true), stage_gpio + RK_GPIO_SWPORT_DDR_L);
	stage_ready = true;

	stage_mark(1);
	return 0;
}
SYS_INIT(stage_pre_kernel_1, PRE_KERNEL_1, 1);

/* ── 단계 2 ─────────────────────────────────────────────────────────────── */
static int stage_pre_kernel_2(void)
{
	stage_mark(2);
	return 0;
}
SYS_INIT(stage_pre_kernel_2, PRE_KERNEL_2, 99);

/* ── 단계 3: 셸 백엔드(POST_KERNEL 90)보다 뒤에 둔다 ────────────────────── */
static int stage_post_kernel(void)
{
	stage_mark(3);
	return 0;
}
SYS_INIT(stage_post_kernel, POST_KERNEL, 99);

/* ── 단계 4: USB 스택(APPLICATION 90)보다 뒤에 둔다 ─────────────────────── */
static int stage_application(void)
{
	stage_mark(4);
	return 0;
}
SYS_INIT(stage_application, APPLICATION, 99);
```
